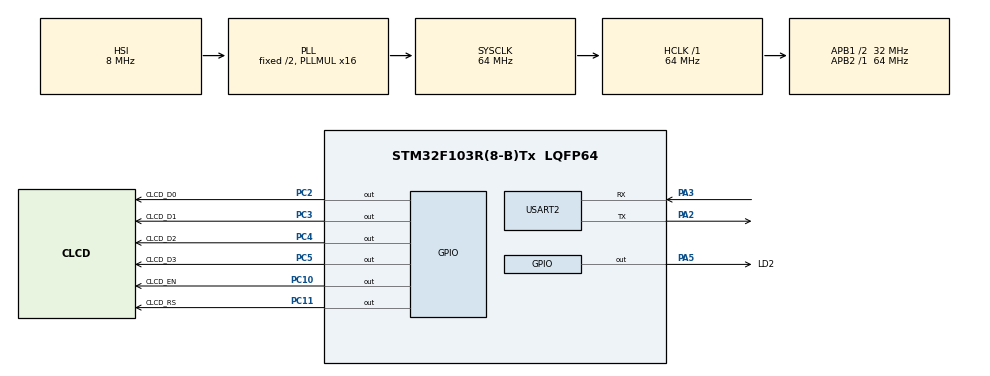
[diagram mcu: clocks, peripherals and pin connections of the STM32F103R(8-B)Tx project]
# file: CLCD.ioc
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Mcu.Family=STM32F1
Mcu.Name=STM32F103R(8-B)Tx
Mcu.Package=LQFP64
NVIC.PriorityGroup=NVIC_PRIORITYGROUP_4
PA13.Mode=Serial_Wire
PA13.Signal=SYS_JTMS-SWDIO
PA14.Mode=Serial_Wire
PA14.Signal=SYS_JTCK-SWCLK
PA2.Mode=Asynchronous
PA2.Signal=USART2_TX
PA3.Mode=Asynchronous
PA3.Signal=USART2_RX
PA5.GPIO_Label=LD2
PA5.Signal=GPIO_Output
PC10.GPIO_Label=CLCD_EN
PC10.Signal=GPIO_Output
PC11.GPIO_Label=CLCD_RS
PC11.Signal=GPIO_Output
PC2.GPIO_Label=CLCD_D0
PC2.Signal=GPIO_Output
PC3.GPIO_Label=CLCD_D1
PC3.Signal=GPIO_Output
PC4.GPIO_Label=CLCD_D2
PC4.Signal=GPIO_Output
PC5.GPIO_Label=CLCD_D3
PC5.Signal=GPIO_Output
ProjectManager.HeapSize=0x200
ProjectManager.StackSize=0x400
ProjectManager.TargetToolchain=STM32CubeIDE
RCC.AHBFreq_Value=64000000
RCC.APB1CLKDivider=RCC_HCLK_DIV2
RCC.APB1Freq_Value=32000000
RCC.APB1TimFreq_Value=64000000
RCC.APB2Freq_Value=64000000
RCC.APB2TimFreq_Value=64000000
RCC.HCLKFreq_Value=64000000
RCC.PLLMUL=RCC_PLL_MUL16
RCC.SYSCLKFreq_VALUE=64000000
RCC.SYSCLKSource=RCC_SYSCLKSOURCE_PLLCLK
RCC.USBFreq_Value=64000000
USART2.VirtualMode=VM_ASYNC
board=custom

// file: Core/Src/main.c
/* USER CODE BEGIN Header */
/**
  ******************************************************************************
  * @file           : main.c
  * @brief          : Main program body
  ******************************************************************************
  * @attention
  *
  * <h2><center>&copy; Copyright (c) 2020 STMicroelectronics.
  * All rights reserved.</center></h2>
  *
  * This software component is licensed by ST under BSD 3-Clause license,
  * the "License"; You may not use this file except in compliance with the
  * License. You may obtain a copy of the License at:
  *                        opensource.org/licenses/BSD-3-Clause
  *
  ******************************************************************************
  */
/* USER CODE END Header */

#include "main.h"

/* USER CODE BEGIN Includes */
#include <stdio.h>
#include "clcd\clcd.h"
/* USER CODE END Includes */

UART_HandleTypeDef huart2;

void SystemClock_Config(void);
static void MX_GPIO_Init(void);
static void MX_USART2_UART_Init(void);

int main(void)
{

  /* MCU Configuration--------------------------------------------------------*/

  /* Reset of all peripherals, Initializes the Flash interface and the Systick. */
  HAL_Init();

  /* Configure the system clock */
  SystemClock_Config();

  /* Initialize all configured peripherals */
  MX_GPIO_Init();
  MX_USART2_UART_Init();
  /* USER CODE BEGIN 2 */
  // LCD 초기화
  CLCD_Init (16, 2);
  CLCD_Puts (0, 0, "NUCLEOEVB");
  CLCD_Puts (0, 1, "HEDY Co.LTD");
  HAL_Delay (1000);

  /* USER CODE END 2 */

  /* Infinite loop */
  /* USER CODE BEGIN WHILE */
  CLCD_Clear ();

  char sBuf[16] = { 0 };
  char count = 0;

  CLCD_Puts (0, 0, "NUCLEOEVB");

  while (1)
    {
      /* USER CODE END WHILE */
      sprintf (sBuf, "Count Num = %3d", count);
      CLCD_Puts (0, 1, sBuf);

      if (count >= 100)
        count = 0;
      else
        count++;

      HAL_Delay (200);
    }
}

void SystemClock_Config(void)
{
  RCC_OscInitTypeDef RCC_OscInitStruct = {0};
  RCC_ClkInitTypeDef RCC_ClkInitStruct = {0};

  /** Initializes the CPU, AHB and APB busses clocks
  */
  RCC_OscInitStruct.OscillatorType = RCC_OSCILLATORTYPE_HSI;
  RCC_OscInitStruct.HSIState = RCC_HSI_ON;
  RCC_OscInitStruct.HSICalibrationValue = RCC_HSICALIBRATION_DEFAULT;
  RCC_OscInitStruct.PLL.PLLState = RCC_PLL_ON;
  RCC_OscInitStruct.PLL.PLLSource = RCC_PLLSOURCE_HSI_DIV2;
  RCC_OscInitStruct.PLL.PLLMUL = RCC_PLL_MUL16;
  if (HAL_RCC_OscConfig(&RCC_OscInitStruct) != HAL_OK)
  {
    Error_Handler();
  }
  /** Initializes the CPU, AHB and APB busses clocks
  */
  RCC_ClkInitStruct.ClockType = RCC_CLOCKTYPE_HCLK|RCC_CLOCKTYPE_SYSCLK
                              |RCC_CLOCKTYPE_PCLK1|RCC_CLOCKTYPE_PCLK2;
  RCC_ClkInitStruct.SYSCLKSource = RCC_SYSCLKSOURCE_PLLCLK;
  RCC_ClkInitStruct.AHBCLKDivider = RCC_SYSCLK_DIV1;
  RCC_ClkInitStruct.APB1CLKDivider = RCC_HCLK_DIV2;
  RCC_ClkInitStruct.APB2CLKDivider = RCC_HCLK_DIV1;

  if (HAL_RCC_ClockConfig(&RCC_ClkInitStruct, FLASH_LATENCY_2) != HAL_OK)
  {
    Error_Handler();
  }
}

static void MX_USART2_UART_Init(void)
{

  huart2.Instance = USART2;
  huart2.Init.BaudRate = 115200;
  huart2.Init.WordLength = UART_WORDLENGTH_8B;
  huart2.Init.StopBits = UART_STOPBITS_1;
  huart2.Init.Parity = UART_PARITY_NONE;
  huart2.Init.Mode = UART_MODE_TX_RX;
  huart2.Init.HwFlowCtl = UART_HWCONTROL_NONE;
  huart2.Init.OverSampling = UART_OVERSAMPLING_16;
  if (HAL_UART_Init(&huart2) != HAL_OK)
  {
    Error_Handler();
  }

}

static void MX_GPIO_Init(void)
{
  GPIO_InitTypeDef GPIO_InitStruct = {0};

  /* GPIO Ports Clock Enable */
  __HAL_RCC_GPIOC_CLK_ENABLE();
  __HAL_RCC_GPIOA_CLK_ENABLE();

  /*Configure GPIO pin Output Level */
  HAL_GPIO_WritePin(GPIOC, CLCD_D0_Pin|CLCD_D1_Pin|CLCD_D2_Pin|CLCD_D3_Pin
                          |CLCD_EN_Pin|CLCD_RS_Pin, GPIO_PIN_RESET);

  /*Configure GPIO pin Output Level */
  HAL_GPIO_WritePin(LD2_GPIO_Port, LD2_Pin, GPIO_PIN_RESET);

  /*Configure GPIO pins : CLCD_D0_Pin CLCD_D1_Pin CLCD_D2_Pin CLCD_D3_Pin
                           CLCD_EN_Pin CLCD_RS_Pin */
  GPIO_InitStruct.Pin = CLCD_D0_Pin|CLCD_D1_Pin|CLCD_D2_Pin|CLCD_D3_Pin
                          |CLCD_EN_Pin|CLCD_RS_Pin;
  GPIO_InitStruct.Mode = GPIO_MODE_OUTPUT_PP;
  GPIO_InitStruct.Pull = GPIO_NOPULL;
  GPIO_InitStruct.Speed = GPIO_SPEED_FREQ_LOW;
  HAL_GPIO_Init(GPIOC, &GPIO_InitStruct);

  /*Configure GPIO pin : LD2_Pin */
  GPIO_InitStruct.Pin = LD2_Pin;
  GPIO_InitStruct.Mode = GPIO_MODE_OUTPUT_PP;
  GPIO_InitStruct.Pull = GPIO_NOPULL;
  GPIO_InitStruct.Speed = GPIO_SPEED_FREQ_LOW;
  HAL_GPIO_Init(LD2_GPIO_Port, &GPIO_InitStruct);

}

void Error_Handler(void)
{
}

/************************ (C) COPYRIGHT STMicroelectronics *****END OF FILE****/
